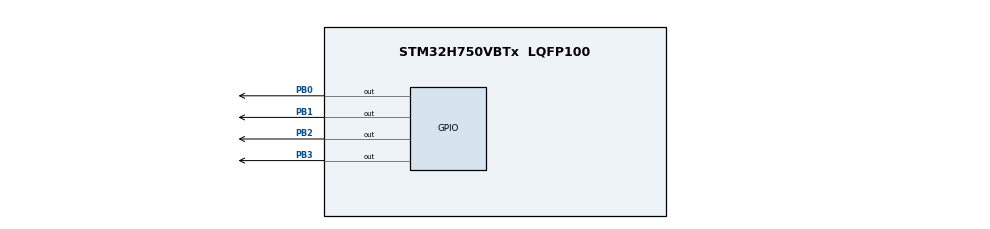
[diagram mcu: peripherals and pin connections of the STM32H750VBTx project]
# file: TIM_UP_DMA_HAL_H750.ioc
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Dma.Request0=TIM3_UP
Dma.TIM3_UP.0.Direction=DMA_MEMORY_TO_PERIPH
Dma.TIM3_UP.0.EventEnable=DISABLE
Dma.TIM3_UP.0.FIFOMode=DMA_FIFOMODE_DISABLE
Dma.TIM3_UP.0.Instance=DMA1_Stream0
Dma.TIM3_UP.0.MemDataAlignment=DMA_MDATAALIGN_WORD
Dma.TIM3_UP.0.MemInc=DMA_MINC_ENABLE
Dma.TIM3_UP.0.Mode=DMA_CIRCULAR
Dma.TIM3_UP.0.PeriphDataAlignment=DMA_PDATAALIGN_WORD
Dma.TIM3_UP.0.PeriphInc=DMA_PINC_DISABLE
Dma.TIM3_UP.0.Polarity=HAL_DMAMUX_REQ_GEN_RISING
Dma.TIM3_UP.0.Priority=DMA_PRIORITY_LOW
Dma.TIM3_UP.0.RequestNumber=1
Dma.TIM3_UP.0.SignalID=NONE
Dma.TIM3_UP.0.SyncEnable=DISABLE
Dma.TIM3_UP.0.SyncPolarity=HAL_DMAMUX_SYNC_NO_EVENT
Dma.TIM3_UP.0.SyncRequestNumber=1
Dma.TIM3_UP.0.SyncSignalID=NONE
Mcu.Family=STM32H7
Mcu.Name=STM32H750VBTx
Mcu.Package=LQFP100
NVIC.DMA1_Stream0_IRQn=true\:0\:0\:false\:false\:true\:false\:true\:true
NVIC.PriorityGroup=NVIC_PRIORITYGROUP_4
PA13\ (JTMS/SWDIO).Mode=Serial_Wire
PA13\ (JTMS/SWDIO).Signal=DEBUG_JTMS-SWDIO
PA14\ (JTCK/SWCLK).Mode=Serial_Wire
PA14\ (JTCK/SWCLK).Signal=DEBUG_JTCK-SWCLK
PB0.Signal=GPIO_Output
PB1.Signal=GPIO_Output
PB2.Signal=GPIO_Output
PB3\ (JTDO/TRACESWO).Signal=GPIO_Output
PH0-OSC_IN\ (PH0).Mode=HSE-External-Oscillator
PH0-OSC_IN\ (PH0).Signal=RCC_OSC_IN
PH1-OSC_OUT\ (PH1).Mode=HSE-External-Oscillator
PH1-OSC_OUT\ (PH1).Signal=RCC_OSC_OUT
ProjectManager.HeapSize=0x200
ProjectManager.StackSize=0x400
ProjectManager.TargetToolchain=STM32CubeIDE
RCC.ADCFreq_Value=50390625
RCC.APB1Freq_Value=120000000
RCC.APB2Freq_Value=120000000
RCC.APB3Freq_Value=120000000
RCC.APB4Freq_Value=120000000
RCC.CortexFreq_Value=240000000
RCC.DIVM1=25
RCC.DIVN1=480
RCC.HCLKFreq_Value=120000000
RCC.HPRE=RCC_HCLK_DIV2
RCC.PLLSourceVirtual=RCC_PLLSOURCE_HSE
RCC.SYSCLKFreq_VALUE=240000000
RCC.SYSCLKSource=RCC_SYSCLKSOURCE_PLLCLK
RCC.USBFreq_Value=240000000
TIM3.AutoReloadPreload=TIM_AUTORELOAD_PRELOAD_ENABLE
TIM3.Period=999
TIM3.Prescaler=119
VP_TIM3_VS_ClockSourceINT.Mode=Internal
board=custom

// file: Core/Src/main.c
/* USER CODE BEGIN Header */
/**
  ******************************************************************************
  * @file           : main.c
  * @brief          : Main program body
  ******************************************************************************
  * @attention
  *
  * Copyright (c) 2023 STMicroelectronics.
  * All rights reserved.
  *
  * This software is licensed under terms that can be found in the LICENSE file
  * in the root directory of this software component.
  * If no LICENSE file comes with this software, it is provided AS-IS.
  *
  ******************************************************************************
  */
/* USER CODE END Header */
#include "main.h"

TIM_HandleTypeDef htim3;
DMA_HandleTypeDef hdma_tim3_up;

void SystemClock_Config(void);
static void MX_GPIO_Init(void);
static void MX_DMA_Init(void);
static void MX_TIM3_Init(void);

int main(void)
{

  /* MCU Configuration--------------------------------------------------------*/

  /* Reset of all peripherals, Initializes the Flash interface and the Systick. */
  HAL_Init();

  /* Configure the system clock */
  SystemClock_Config();

  /* Initialize all configured peripherals */
  MX_GPIO_Init();
  MX_DMA_Init();
  MX_TIM3_Init();

  /* Infinite loop */
  /* USER CODE BEGIN WHILE */

  // BSRR寄存器数据，高16位用于清除端口，低16位用于设置端口
  uint32_t buff[5] ={0x000F0000, 0x00000008, 0x00000004, 0x00000002, 0x00000001};

  // 以下步骤参考函数 HAL_TIM_Base_Start_DMA ，但该函数中外设地址是定时器的ARR寄存器，不符合我这里需求，所以根据该函数来编写下面代码
  HAL_DMA_Start(&hdma_tim3_up, (uint32_t)buff, (uint32_t)&GPIOB->BSRR, 5);
  __HAL_TIM_ENABLE_DMA(&htim3, TIM_DMA_UPDATE);
  HAL_TIM_Base_Start(&htim3);

  while (1)
  {
    /* USER CODE END WHILE */

  }
}

void SystemClock_Config(void)
{
  RCC_OscInitTypeDef RCC_OscInitStruct = {0};
  RCC_ClkInitTypeDef RCC_ClkInitStruct = {0};

  /** Supply configuration update enable
  */
  HAL_PWREx_ConfigSupply(PWR_LDO_SUPPLY);

  /** Configure the main internal regulator output voltage
  */
  __HAL_PWR_VOLTAGESCALING_CONFIG(PWR_REGULATOR_VOLTAGE_SCALE2);

  while(!__HAL_PWR_GET_FLAG(PWR_FLAG_VOSRDY)) {}

  /** Initializes the RCC Oscillators according to the specified parameters
  * in the RCC_OscInitTypeDef structure.
  */
  RCC_OscInitStruct.OscillatorType = RCC_OSCILLATORTYPE_HSE;
  RCC_OscInitStruct.HSEState = RCC_HSE_ON;
  RCC_OscInitStruct.PLL.PLLState = RCC_PLL_ON;
  RCC_OscInitStruct.PLL.PLLSource = RCC_PLLSOURCE_HSE;
  RCC_OscInitStruct.PLL.PLLM = 25;
  RCC_OscInitStruct.PLL.PLLN = 480;
  RCC_OscInitStruct.PLL.PLLP = 2;
  RCC_OscInitStruct.PLL.PLLQ = 2;
  RCC_OscInitStruct.PLL.PLLR = 2;
  RCC_OscInitStruct.PLL.PLLRGE = RCC_PLL1VCIRANGE_0;
  RCC_OscInitStruct.PLL.PLLVCOSEL = RCC_PLL1VCOWIDE;
  RCC_OscInitStruct.PLL.PLLFRACN = 0;
  if (HAL_RCC_OscConfig(&RCC_OscInitStruct) != HAL_OK)
  {
    Error_Handler();
  }

  /** Initializes the CPU, AHB and APB buses clocks
  */
  RCC_ClkInitStruct.ClockType = RCC_CLOCKTYPE_HCLK|RCC_CLOCKTYPE_SYSCLK
                              |RCC_CLOCKTYPE_PCLK1|RCC_CLOCKTYPE_PCLK2
                              |RCC_CLOCKTYPE_D3PCLK1|RCC_CLOCKTYPE_D1PCLK1;
  RCC_ClkInitStruct.SYSCLKSource = RCC_SYSCLKSOURCE_PLLCLK;
  RCC_ClkInitStruct.SYSCLKDivider = RCC_SYSCLK_DIV1;
  RCC_ClkInitStruct.AHBCLKDivider = RCC_HCLK_DIV2;
  RCC_ClkInitStruct.APB3CLKDivider = RCC_APB3_DIV1;
  RCC_ClkInitStruct.APB1CLKDivider = RCC_APB1_DIV1;
  RCC_ClkInitStruct.APB2CLKDivider = RCC_APB2_DIV1;
  RCC_ClkInitStruct.APB4CLKDivider = RCC_APB4_DIV1;

  if (HAL_RCC_ClockConfig(&RCC_ClkInitStruct, FLASH_LATENCY_2) != HAL_OK)
  {
    Error_Handler();
  }
}

static void MX_TIM3_Init(void)
{

  TIM_ClockConfigTypeDef sClockSourceConfig = {0};
  TIM_MasterConfigTypeDef sMasterConfig = {0};

  htim3.Instance = TIM3;
  htim3.Init.Prescaler = 119;
  htim3.Init.CounterMode = TIM_COUNTERMODE_UP;
  htim3.Init.Period = 999;
  htim3.Init.ClockDivision = TIM_CLOCKDIVISION_DIV1;
  htim3.Init.AutoReloadPreload = TIM_AUTORELOAD_PRELOAD_ENABLE;
  if (HAL_TIM_Base_Init(&htim3) != HAL_OK)
  {
    Error_Handler();
  }
  sClockSourceConfig.ClockSource = TIM_CLOCKSOURCE_INTERNAL;
  if (HAL_TIM_ConfigClockSource(&htim3, &sClockSourceConfig) != HAL_OK)
  {
    Error_Handler();
  }
  sMasterConfig.MasterOutputTrigger = TIM_TRGO_RESET;
  sMasterConfig.MasterSlaveMode = TIM_MASTERSLAVEMODE_DISABLE;
  if (HAL_TIMEx_MasterConfigSynchronization(&htim3, &sMasterConfig) != HAL_OK)
  {
    Error_Handler();
  }

}

static void MX_DMA_Init(void)
{

  /* DMA controller clock enable */
  __HAL_RCC_DMA1_CLK_ENABLE();

  /* DMA interrupt init */
  /* DMA1_Stream0_IRQn interrupt configuration */
  HAL_NVIC_SetPriority(DMA1_Stream0_IRQn, 0, 0);
  HAL_NVIC_EnableIRQ(DMA1_Stream0_IRQn);

}

static void MX_GPIO_Init(void)
{
  GPIO_InitTypeDef GPIO_InitStruct = {0};

  /* GPIO Ports Clock Enable */
  __HAL_RCC_GPIOH_CLK_ENABLE();
  __HAL_RCC_GPIOB_CLK_ENABLE();
  __HAL_RCC_GPIOA_CLK_ENABLE();

  /*Configure GPIO pin Output Level */
  HAL_GPIO_WritePin(GPIOB, GPIO_PIN_0|GPIO_PIN_1|GPIO_PIN_2|GPIO_PIN_3, GPIO_PIN_RESET);

  /*Configure GPIO pins : PB0 PB1 PB2 PB3 */
  GPIO_InitStruct.Pin = GPIO_PIN_0|GPIO_PIN_1|GPIO_PIN_2|GPIO_PIN_3;
  GPIO_InitStruct.Mode = GPIO_MODE_OUTPUT_PP;
  GPIO_InitStruct.Pull = GPIO_NOPULL;
  GPIO_InitStruct.Speed = GPIO_SPEED_FREQ_LOW;
  HAL_GPIO_Init(GPIOB, &GPIO_InitStruct);

}

void Error_Handler(void)
{
  __disable_irq();
  while (1)
  {
  }
}
